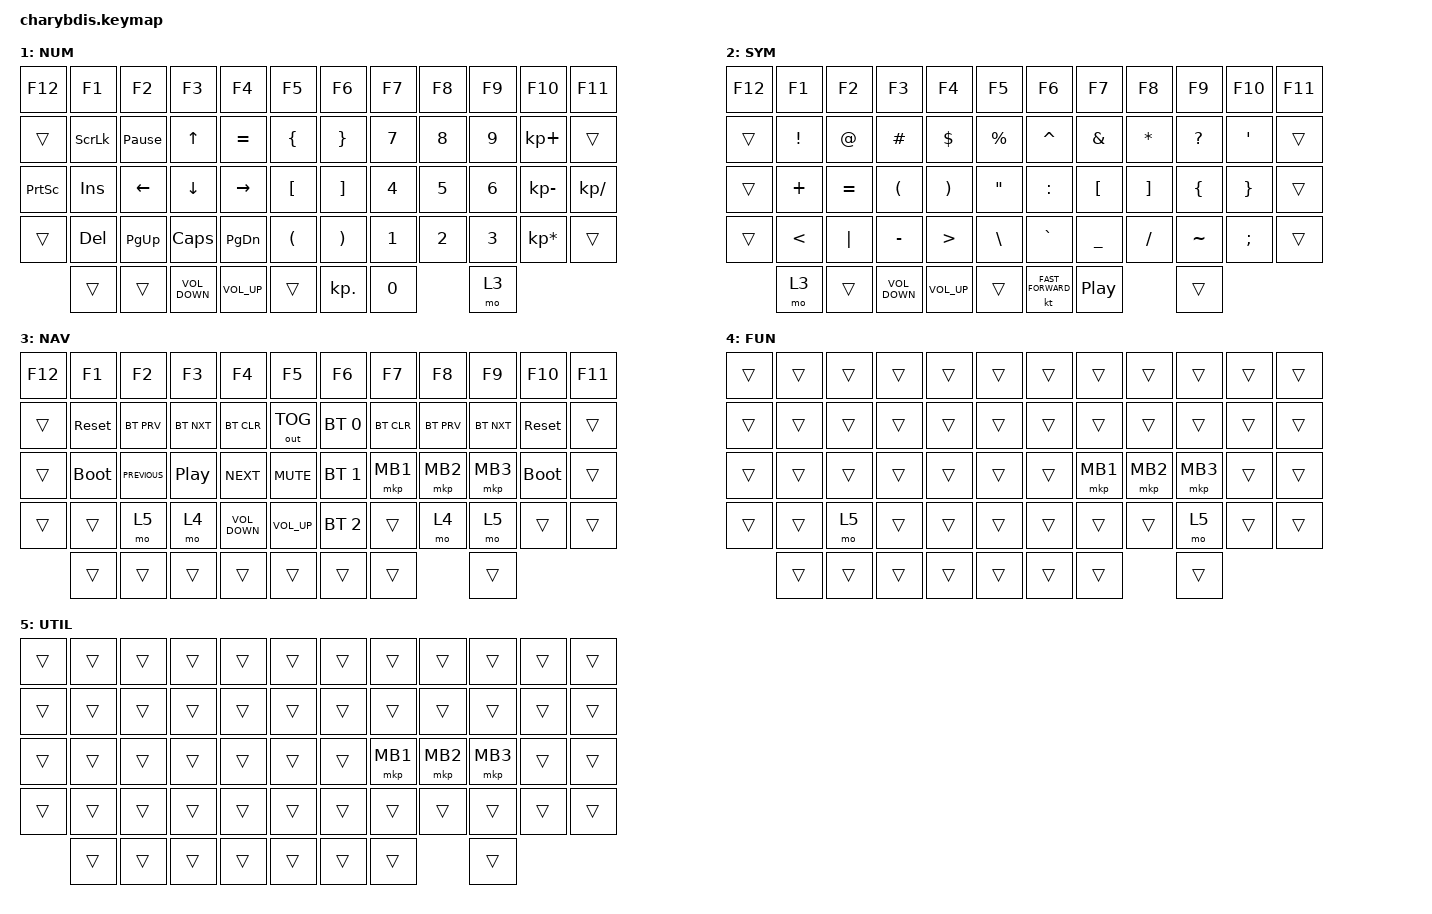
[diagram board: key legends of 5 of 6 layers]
#include <dt-bindings/zmk/mouse.h>
#include <behaviors/mouse_keys.dtsi>
#include <behaviors.dtsi>
#include <dt-bindings/zmk/bt.h>
#include <dt-bindings/zmk/keys.h>
#include <dt-bindings/zmk/outputs.h>
#include <dt-bindings/zmk/pointing.h>

#define ABC 0
#define NUM 1
#define SYM 2
#define NAV 3
#define FUN 4
#define UTIL 5

// Home row mods macro
#define HRML(k1,k2,k3,k4) &ht LGUI k1  &ht LALT k2  &ht LCTRL k3  &ht LSHIFT k4
#define HRMR(k1,k2,k3,k4) &ht RSHIFT k1  &ht RCTRL k2  &ht RALT k3  &ht RGUI k4

/ {
	
	behaviors {
		ht: hold_tap {
			label = "hold_tap";
            compatible = "zmk,behavior-hold-tap";
            #binding-cells = <2>;
            flavor = "tap-preferred";
            tapping-term-ms = <180>;
            quick-tap-ms = <100>;
            require-prior-idle-ms = <100>;
            bindings = <&kp>, <&kp>;
        };
        btht: bluetooth_hold_tap {
            compatible = "zmk,behavior-hold-tap";
            #binding-cells = <2>;
            flavor = "tap-preferred";
            tapping-term-ms = <2000>;
            require-prior-idle-ms = <100>;
            bindings = <&btdis>, <&btsel>;
        };
        tdto0: tap_dance_to_layer_0 {
            compatible = "zmk,behavior-tap-dance";
            #binding-cells = <0>;
            tapping-term-ms = <200>;
            bindings = <&none>, <&to 0>;
        };
		mmv {
			acceleration-exponent = <1>;// 1
			time-to-max-speed-ms = <300>;// 40
			delay-ms = <0>;// 0
		};
		msc {
			acceleration-exponent = <0>;// 0
			time-to-max-speed-ms = <40>;// 500
			delay-ms = <0>;// 10
		};
	};
//End of behaviors

    macros {
        btsel: bluetooth_select {
            compatible = "zmk,behavior-macro-one-param";
            #binding-cells = <1>;
            bindings
                = <&macro_param_1to2>
                , <&macro_tap &bt BT_SEL MACRO_PLACEHOLDER>
                , <&macro_tap &out OUT_BLE>
                ;
        };
        btdis: bluetooth_disconnect {
            compatible = "zmk,behavior-macro-one-param";
            #binding-cells = <1>;
            bindings
                = <&macro_param_1to2>
                , <&macro_tap &bt BT_DISC MACRO_PLACEHOLDER>
                ;
        };
    };
//End of macros
	
	conditional_layers {
		compatible = "zmk,conditional-layers";
		
		tri_layer {
			if-layers = <NAV FUN>;
			then-layer = <UTIL>;
		};
	};

	combos {
		compatible = "zmk,combos";

		combo_fp_left_click {
			timeout-ms = <25>;
			require-prior-idle-ms = <125>;
			key-positions = <12 13>;
			layers = <ABC NUM NAV>;
			bindings = <&mkp RCLK>;
		};

		combo_cv_right_click {
			timeout-ms = <25>;
			require-prior-idle-ms = <125>;
			key-positions = <22 23>;
			layers = <ABC NUM NAV>;
			bindings = <&mkp RCLK>;
		};
        combo_caps_word {
            timeout-ms = <30>;
            key-positions = <2 3>;
            bindings = <&caps_word>;
        };
        combo_del {
            timeout-ms = <30>;
            key-positions = <6 7>;
            bindings = <&kp DEL>;
        };
        combo_esc {
            timeout-ms = <30>;
            key-positions = <0 1>;
            bindings = <&kp ESC>;
        };
        combo_navlock {
            timeout-ms = <30>;
            key-positions = <26 28>;
            bindings = <&to 3>;
        };
	};
//End of combos
	
	keymap {
		compatible = "zmk,keymap";

        default_layer {
			display-name = "ABC";
            bindings = <
        //╭──────────┬──────────┬──────────┬──────────┬──────────┬──────────╮   ╭──────────┬──────────┬──────────┬──────────┬──────────┬──────────╮
        //  backtick │ 1        │ 2        │ 3        │ 4        │ 5        │   │ 6        │ 7        │ 8        │ 9        │  0       │ Minus   │
           &kp GRAVE   &kp N1     &kp N2     &kp N3     &kp N4     &kp N5         &kp N6     &kp N7     &kp N8     &kp N9     &kp N0     &kp MINUS
        //├──────────┼──────────┼──────────┼──────────┼──────────┼──────────┤   ├──────────┼──────────┼──────────┼──────────┼──────────┼──────────┤
        //│   TAB    │  Q       │  W       │  F       │  P       │  B       │   │  J       │  L       │  U       │  Y       │ ' "      │ Backslash
            &kp TAB    &kp Q      &kp W      &kp F      &lt NAV P  &kp B          &kp J      &kp L      &kp U      &kp Y      &kp SQT    &kp BSLH
        //├──────────┼──────────┼──────────┼──────────┼──────────┼──────────┤   ├──────────┼──────────┼──────────┼──────────┼──────────┼──────────┤
        //│   SHIFT  │ A        │  R       │  S       │  T       │  G       │   │  M       │  N       │  E       │  I       │ O        │ Shift
           &kp LSHIFT  HRML(A,        R,         S,         T)     &kp G          &kp M      HRMR(N,        E,         I,        O)      &kp RSHIFT
        //├──────────┼──────────┼──────────┼──────────┼──────────┼──────────┤   ├──────────┼──────────┼──────────┼──────────┼──────────┼──────────┤
        //│   CTRL   │ Z        │  X       │  C       │  D       │  V       │   │  K       │  H       │ , <      │ . >      │ / ?      │ Alt
           &kp LCTRL   &lt FUN Z  &kp X      &lt SYM C  &lt NUM D  &kp V          &kp K      &kp H      &kp COMMA  &kp DOT    &kp FSLH   &kp RALT
        //╰──────────┴──────────┴──────────┴──────────┼──────────┼──────────┤   ├──────────┴──────────┼──────────┼──────────┴──────────┴──────────╯
                &lt NAV SPACE &kp LSHIFT &kp ENTER     &lt NUM     &kp TAB       &kp SPACE   &kp RSHIFT  &kp BSPC
        //       ╰──────────┴──────────┴──────────╯   ╰──────────┴──────────╯   ╰──────────┴──────────┴──────────╯
            >;
        };

        NUM {
            bindings = <
&kp F12          &kp F1          &kp F2           &kp F3             &kp F4           &kp F5    &kp F6                &kp F7  &kp F8  &kp F9  &kp F10          &kp F11
&trans           &kp SCROLLLOCK  &kp PAUSE_BREAK  &kp UP             &kp EQUAL        &kp LBRC              &kp RBRC  &kp N7  &kp N8  &kp N9  &kp KP_PLUS      &trans
&kp PRINTSCREEN  &kp INSERT      &kp LEFT         &kp DOWN           &kp RIGHT        &kp LBKT              &kp RBKT  &kp N4  &kp N5  &kp N6  &kp KP_MINUS     &kp KP_DIVIDE
&trans           &kp DEL         &kp PG_UP        &kp CAPS           &kp PG_DN        &kp LPAR              &kp RPAR  &kp N1  &kp N2  &kp N3  &kp KP_MULTIPLY  &trans
                 &trans          &trans           &kp C_VOLUME_DOWN  &kp C_VOLUME_UP  &trans    &kp KP_DOT            &kp N0          &mo 3
            >;
        };

        SYM {
            bindings = <
&kp F12  &kp F1         &kp F2     &kp F3             &kp F4            &kp F5         &kp F6                         &kp F7            &kp F8     &kp F9        &kp F10        &kp F11
&trans   &kp EXCL       &kp AT     &kp HASH           &kp DLLR          &kp PRCNT                          &kp CARET  &kp AMPS          &kp STAR   &kp QUESTION  &kp SQT        &trans
&trans   &kp PLUS       &kp EQUAL  &kp LPAR           &kp RPAR          &kp DQT                            &kp COLON  &kp LBKT          &kp RBKT   &kp LBRC      &kp RBRC       &trans
&trans   &kp LESS_THAN  &kp PIPE   &kp MINUS          &kp GREATER_THAN  &kp BACKSLASH                      &kp GRAVE  &kp UNDERSCORE    &kp SLASH  &kp TILDE     &kp SEMICOLON  &trans
         &mo 3          &trans     &kp C_VOLUME_DOWN  &kp C_VOLUME_UP   &trans         &kt C_FAST_FORWARD             &kp C_PLAY_PAUSE             &trans
            >;
        };

        NAV {
            bindings = <
&kp F12  &kp F1       &kp F2          &kp F3            &kp F4             &kp F5           &kp F6                &kp F7      &kp F8      &kp F9      &kp F10      &kp F11
&trans   &sys_reset   &bt BT_PRV      &bt BT_NXT        &bt BT_CLR         &out OUT_TOG             &bt BT_SEL 0  &bt BT_CLR  &bt BT_PRV  &bt BT_NXT  &sys_reset   &trans
&trans   &bootloader  &kp C_PREVIOUS  &kp C_PLAY_PAUSE  &kp C_NEXT         &kp C_MUTE               &bt BT_SEL 1  &mkp MB1    &mkp MB2    &mkp MB3    &bootloader  &trans
&trans   &trans       &mo 5           &mo 4             &kp C_VOLUME_DOWN  &kp C_VOLUME_UP          &bt BT_SEL 2  &trans      &mo 4       &mo 5       &trans       &trans
         &trans       &trans          &trans            &trans             &trans           &trans                &trans                  &trans
            >;
        };

        FUN {
            bindings = <
&trans  &trans  &trans  &trans  &trans  &trans  &trans          &trans    &trans    &trans    &trans  &trans
&trans  &trans  &trans  &trans  &trans  &trans          &trans  &trans    &trans    &trans    &trans  &trans
&trans  &trans  &trans  &trans  &trans  &trans          &trans  &mkp MB1  &mkp MB2  &mkp MB3  &trans  &trans
&trans  &trans  &mo 5   &trans  &trans  &trans          &trans  &trans    &trans    &mo 5     &trans  &trans
        &trans  &trans  &trans  &trans  &trans  &trans          &trans              &trans
            >;
        };

        UTIL {
            bindings = <
&trans  &trans  &trans  &trans  &trans  &trans  &trans          &trans    &trans    &trans    &trans  &trans
&trans  &trans  &trans  &trans  &trans  &trans          &trans  &trans    &trans    &trans    &trans  &trans
&trans  &trans  &trans  &trans  &trans  &trans          &trans  &mkp MB1  &mkp MB2  &mkp MB3  &trans  &trans
&trans  &trans  &trans  &trans  &trans  &trans          &trans  &trans    &trans    &trans    &trans  &trans
        &trans  &trans  &trans  &trans  &trans  &trans          &trans              &trans
            >;
        };
    };
};
